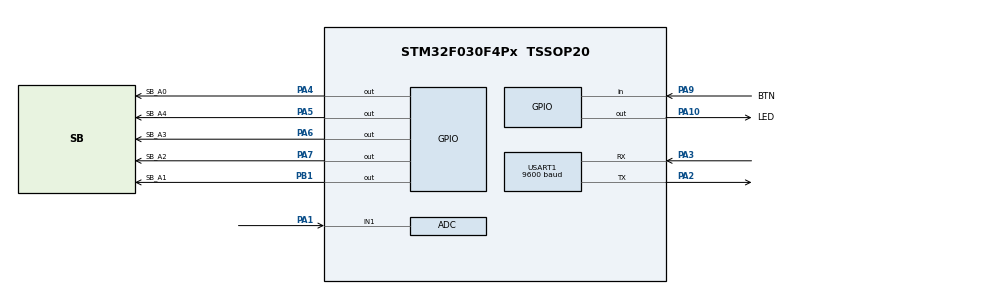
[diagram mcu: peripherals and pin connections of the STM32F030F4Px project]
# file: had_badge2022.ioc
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ADC.ClockPrescaler=ADC_CLOCK_ASYNC_DIV1
ADC.SamplingTime=ADC_SAMPLETIME_55CYCLES_5
Dma.ADC.0.Direction=DMA_PERIPH_TO_MEMORY
Dma.ADC.0.Instance=DMA1_Channel1
Dma.ADC.0.MemDataAlignment=DMA_MDATAALIGN_HALFWORD
Dma.ADC.0.MemInc=DMA_MINC_ENABLE
Dma.ADC.0.Mode=DMA_CIRCULAR
Dma.ADC.0.PeriphDataAlignment=DMA_PDATAALIGN_HALFWORD
Dma.ADC.0.PeriphInc=DMA_PINC_DISABLE
Dma.ADC.0.Priority=DMA_PRIORITY_LOW
Dma.Request0=ADC
Mcu.Family=STM32F0
Mcu.Name=STM32F030F4Px
Mcu.Package=TSSOP20
NVIC.DMA1_Channel1_IRQn=true\:0\:0\:false\:false\:true\:false\:true\:true
NVIC.TIM1_BRK_UP_TRG_COM_IRQn=true\:0\:0\:false\:false\:true\:true\:true\:true
PA0.Signal=ADC_IN0
PA1.Mode=IN1
PA1.Signal=ADC_IN1
PA10.GPIO_Label=LED
PA10.Signal=GPIO_Output
PA13.Mode=Serial_Wire
PA13.Signal=SYS_SWDIO
PA14.Mode=Serial_Wire
PA14.Signal=SYS_SWCLK
PA2.Mode=Asynchronous
PA2.Signal=USART1_TX
PA3.Mode=Asynchronous
PA3.Signal=USART1_RX
PA4.GPIO_Label=SB_A0
PA4.Signal=GPIO_Output
PA5.GPIO_Label=SB_A4
PA5.Signal=GPIO_Output
PA6.GPIO_Label=SB_A3
PA6.Signal=GPIO_Output
PA7.GPIO_Label=SB_A2
PA7.Signal=GPIO_Output
PA9.GPIO_Label=BTN
PA9.GPIO_PuPd=GPIO_PULLUP
PA9.Signal=GPIO_Input
PB1.GPIO_Label=SB_A1
PB1.Signal=GPIO_Output
ProjectManager.HeapSize=0x200
ProjectManager.StackSize=0x400
ProjectManager.TargetToolchain=STM32CubeIDE
RCC.AHBFreq_Value=48000000
RCC.APB1Freq_Value=48000000
RCC.APB1TimFreq_Value=48000000
RCC.HCLKFreq_Value=48000000
RCC.PLLMUL=RCC_PLL_MUL12
RCC.SYSCLKFreq_VALUE=48000000
RCC.SYSCLKSource=RCC_SYSCLKSOURCE_PLLCLK
TIM1.AutoReloadPreload=TIM_AUTORELOAD_PRELOAD_ENABLE
TIM1.Period=4799
TIM1.TIM_MasterOutputTrigger=TIM_TRGO_UPDATE
USART1.BaudRate=9600
USART1.VirtualMode-Asynchronous=VM_ASYNC
VP_TIM1_VS_ClockSourceINT.Mode=Internal
board=custom

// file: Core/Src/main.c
/* USER CODE BEGIN Header */
/**
  ******************************************************************************
  * @file           : main.c
  * @brief          : Main program body
  ******************************************************************************
  * @attention
  *
  * Copyright (c) 2022 STMicroelectronics.
  * All rights reserved.
  *
  * This software is licensed under terms that can be found in the LICENSE file
  * in the root directory of this software component.
  * If no LICENSE file comes with this software, it is provided AS-IS.
  *
  ******************************************************************************
  */
/* USER CODE END Header */
#include "main.h"

void SystemClock_Config(void);
static void MX_GPIO_Init(void);
static void MX_DMA_Init(void);
static void MX_ADC_Init(void);
static void MX_TIM1_Init(void);
static void MX_USART1_UART_Init(void);

int main(void)
{

  /* MCU Configuration--------------------------------------------------------*/

  /* Reset of all peripherals, Initializes the Flash interface and the Systick. */
  LL_APB1_GRP2_EnableClock(LL_APB1_GRP2_PERIPH_SYSCFG);
  LL_APB1_GRP1_EnableClock(LL_APB1_GRP1_PERIPH_PWR);

  /* SysTick_IRQn interrupt configuration */
  NVIC_SetPriority(SysTick_IRQn, 3);

  /* Configure the system clock */
  SystemClock_Config();

  /* Initialize all configured peripherals */
  MX_GPIO_Init();
  MX_DMA_Init();
  MX_ADC_Init();
  MX_TIM1_Init();
  MX_USART1_UART_Init();

  /* Infinite loop */
  /* USER CODE BEGIN WHILE */
  run();
    /* USER CODE END WHILE */

}

void SystemClock_Config(void)
{
  LL_FLASH_SetLatency(LL_FLASH_LATENCY_1);
  while(LL_FLASH_GetLatency() != LL_FLASH_LATENCY_1)
  {
  }
  LL_RCC_HSI_Enable();

   /* Wait till HSI is ready */
  while(LL_RCC_HSI_IsReady() != 1)
  {

  }
  LL_RCC_HSI_SetCalibTrimming(16);
  LL_RCC_HSI14_Enable();

   /* Wait till HSI14 is ready */
  while(LL_RCC_HSI14_IsReady() != 1)
  {

  }
  LL_RCC_HSI14_SetCalibTrimming(16);
  LL_RCC_PLL_ConfigDomain_SYS(LL_RCC_PLLSOURCE_HSI_DIV_2, LL_RCC_PLL_MUL_12);
  LL_RCC_PLL_Enable();

   /* Wait till PLL is ready */
  while(LL_RCC_PLL_IsReady() != 1)
  {

  }
  LL_RCC_SetAHBPrescaler(LL_RCC_SYSCLK_DIV_1);
  LL_RCC_SetAPB1Prescaler(LL_RCC_APB1_DIV_1);
  LL_RCC_SetSysClkSource(LL_RCC_SYS_CLKSOURCE_PLL);

   /* Wait till System clock is ready */
  while(LL_RCC_GetSysClkSource() != LL_RCC_SYS_CLKSOURCE_STATUS_PLL)
  {

  }
  LL_Init1msTick(48000000);
  LL_SetSystemCoreClock(48000000);
  LL_RCC_HSI14_EnableADCControl();
  LL_RCC_SetUSARTClockSource(LL_RCC_USART1_CLKSOURCE_PCLK1);
}

static void MX_ADC_Init(void)
{

  LL_ADC_InitTypeDef ADC_InitStruct = {0};
  LL_ADC_REG_InitTypeDef ADC_REG_InitStruct = {0};

  LL_GPIO_InitTypeDef GPIO_InitStruct = {0};

  /* Peripheral clock enable */
  LL_APB1_GRP2_EnableClock(LL_APB1_GRP2_PERIPH_ADC1);

  LL_AHB1_GRP1_EnableClock(LL_AHB1_GRP1_PERIPH_GPIOA);
  /**ADC GPIO Configuration
  PA0   ------> ADC_IN0
  PA1   ------> ADC_IN1
  */
  GPIO_InitStruct.Pin = LL_GPIO_PIN_0;
  GPIO_InitStruct.Mode = LL_GPIO_MODE_ANALOG;
  GPIO_InitStruct.Pull = LL_GPIO_PULL_NO;
  LL_GPIO_Init(GPIOA, &GPIO_InitStruct);

  GPIO_InitStruct.Pin = LL_GPIO_PIN_1;
  GPIO_InitStruct.Mode = LL_GPIO_MODE_ANALOG;
  GPIO_InitStruct.Pull = LL_GPIO_PULL_NO;
  LL_GPIO_Init(GPIOA, &GPIO_InitStruct);

  /* ADC DMA Init */

  /* ADC Init */
  LL_DMA_SetDataTransferDirection(DMA1, LL_DMA_CHANNEL_1, LL_DMA_DIRECTION_PERIPH_TO_MEMORY);

  LL_DMA_SetChannelPriorityLevel(DMA1, LL_DMA_CHANNEL_1, LL_DMA_PRIORITY_LOW);

  LL_DMA_SetMode(DMA1, LL_DMA_CHANNEL_1, LL_DMA_MODE_CIRCULAR);

  LL_DMA_SetPeriphIncMode(DMA1, LL_DMA_CHANNEL_1, LL_DMA_PERIPH_NOINCREMENT);

  LL_DMA_SetMemoryIncMode(DMA1, LL_DMA_CHANNEL_1, LL_DMA_MEMORY_INCREMENT);

  LL_DMA_SetPeriphSize(DMA1, LL_DMA_CHANNEL_1, LL_DMA_PDATAALIGN_HALFWORD);

  LL_DMA_SetMemorySize(DMA1, LL_DMA_CHANNEL_1, LL_DMA_MDATAALIGN_HALFWORD);

  /** Configure Regular Channel
  */
  LL_ADC_REG_SetSequencerChAdd(ADC1, LL_ADC_CHANNEL_1);

  /** Configure the global features of the ADC (Clock, Resolution, Data Alignment and number of conversion)
  */
  ADC_InitStruct.Clock = LL_ADC_CLOCK_ASYNC;
  ADC_InitStruct.Resolution = LL_ADC_RESOLUTION_12B;
  ADC_InitStruct.DataAlignment = LL_ADC_DATA_ALIGN_RIGHT;
  ADC_InitStruct.LowPowerMode = LL_ADC_LP_MODE_NONE;
  LL_ADC_Init(ADC1, &ADC_InitStruct);
  ADC_REG_InitStruct.TriggerSource = LL_ADC_REG_TRIG_SOFTWARE;
  ADC_REG_InitStruct.SequencerDiscont = LL_ADC_REG_SEQ_DISCONT_DISABLE;
  ADC_REG_InitStruct.ContinuousMode = LL_ADC_REG_CONV_SINGLE;
  ADC_REG_InitStruct.DMATransfer = LL_ADC_REG_DMA_TRANSFER_LIMITED;
  ADC_REG_InitStruct.Overrun = LL_ADC_REG_OVR_DATA_PRESERVED;
  LL_ADC_REG_Init(ADC1, &ADC_REG_InitStruct);
  LL_ADC_REG_SetSequencerScanDirection(ADC1, LL_ADC_REG_SEQ_SCAN_DIR_FORWARD);
  LL_ADC_SetSamplingTimeCommonChannels(ADC1, LL_ADC_SAMPLINGTIME_55CYCLES_5);

}

static void MX_TIM1_Init(void)
{

  LL_TIM_InitTypeDef TIM_InitStruct = {0};

  /* Peripheral clock enable */
  LL_APB1_GRP2_EnableClock(LL_APB1_GRP2_PERIPH_TIM1);

  /* TIM1 interrupt Init */
  NVIC_SetPriority(TIM1_BRK_UP_TRG_COM_IRQn, 0);
  NVIC_EnableIRQ(TIM1_BRK_UP_TRG_COM_IRQn);

  TIM_InitStruct.Prescaler = 0;
  TIM_InitStruct.CounterMode = LL_TIM_COUNTERMODE_UP;
  TIM_InitStruct.Autoreload = 4799;
  TIM_InitStruct.ClockDivision = LL_TIM_CLOCKDIVISION_DIV1;
  TIM_InitStruct.RepetitionCounter = 0;
  LL_TIM_Init(TIM1, &TIM_InitStruct);
  LL_TIM_EnableARRPreload(TIM1);
  LL_TIM_SetClockSource(TIM1, LL_TIM_CLOCKSOURCE_INTERNAL);
  LL_TIM_SetTriggerOutput(TIM1, LL_TIM_TRGO_UPDATE);
  LL_TIM_DisableMasterSlaveMode(TIM1);

}

static void MX_USART1_UART_Init(void)
{

  LL_USART_InitTypeDef USART_InitStruct = {0};

  LL_GPIO_InitTypeDef GPIO_InitStruct = {0};

  /* Peripheral clock enable */
  LL_APB1_GRP2_EnableClock(LL_APB1_GRP2_PERIPH_USART1);

  LL_AHB1_GRP1_EnableClock(LL_AHB1_GRP1_PERIPH_GPIOA);
  /**USART1 GPIO Configuration
  PA2   ------> USART1_TX
  PA3   ------> USART1_RX
  */
  GPIO_InitStruct.Pin = LL_GPIO_PIN_2;
  GPIO_InitStruct.Mode = LL_GPIO_MODE_ALTERNATE;
  GPIO_InitStruct.Speed = LL_GPIO_SPEED_FREQ_HIGH;
  GPIO_InitStruct.OutputType = LL_GPIO_OUTPUT_PUSHPULL;
  GPIO_InitStruct.Pull = LL_GPIO_PULL_NO;
  GPIO_InitStruct.Alternate = LL_GPIO_AF_1;
  LL_GPIO_Init(GPIOA, &GPIO_InitStruct);

  GPIO_InitStruct.Pin = LL_GPIO_PIN_3;
  GPIO_InitStruct.Mode = LL_GPIO_MODE_ALTERNATE;
  GPIO_InitStruct.Speed = LL_GPIO_SPEED_FREQ_HIGH;
  GPIO_InitStruct.OutputType = LL_GPIO_OUTPUT_PUSHPULL;
  GPIO_InitStruct.Pull = LL_GPIO_PULL_NO;
  GPIO_InitStruct.Alternate = LL_GPIO_AF_1;
  LL_GPIO_Init(GPIOA, &GPIO_InitStruct);

  USART_InitStruct.BaudRate = 9600;
  USART_InitStruct.DataWidth = LL_USART_DATAWIDTH_8B;
  USART_InitStruct.StopBits = LL_USART_STOPBITS_1;
  USART_InitStruct.Parity = LL_USART_PARITY_NONE;
  USART_InitStruct.TransferDirection = LL_USART_DIRECTION_TX_RX;
  USART_InitStruct.HardwareFlowControl = LL_USART_HWCONTROL_NONE;
  USART_InitStruct.OverSampling = LL_USART_OVERSAMPLING_16;
  LL_USART_Init(USART1, &USART_InitStruct);
  LL_USART_DisableIT_CTS(USART1);
  LL_USART_ConfigAsyncMode(USART1);
  LL_USART_Enable(USART1);

}

static void MX_DMA_Init(void)
{

  /* Init with LL driver */
  /* DMA controller clock enable */
  LL_AHB1_GRP1_EnableClock(LL_AHB1_GRP1_PERIPH_DMA1);

  /* DMA interrupt init */
  /* DMA1_Channel1_IRQn interrupt configuration */
  NVIC_SetPriority(DMA1_Channel1_IRQn, 0);
  NVIC_EnableIRQ(DMA1_Channel1_IRQn);

}

static void MX_GPIO_Init(void)
{
  LL_GPIO_InitTypeDef GPIO_InitStruct = {0};

  /* GPIO Ports Clock Enable */
  LL_AHB1_GRP1_EnableClock(LL_AHB1_GRP1_PERIPH_GPIOA);
  LL_AHB1_GRP1_EnableClock(LL_AHB1_GRP1_PERIPH_GPIOB);

  /**/
  LL_GPIO_ResetOutputPin(SB_A0_GPIO_Port, SB_A0_Pin);

  /**/
  LL_GPIO_ResetOutputPin(SB_A4_GPIO_Port, SB_A4_Pin);

  /**/
  LL_GPIO_ResetOutputPin(SB_A3_GPIO_Port, SB_A3_Pin);

  /**/
  LL_GPIO_ResetOutputPin(SB_A2_GPIO_Port, SB_A2_Pin);

  /**/
  LL_GPIO_ResetOutputPin(SB_A1_GPIO_Port, SB_A1_Pin);

  /**/
  LL_GPIO_ResetOutputPin(LED_GPIO_Port, LED_Pin);

  /**/
  GPIO_InitStruct.Pin = SB_A0_Pin;
  GPIO_InitStruct.Mode = LL_GPIO_MODE_OUTPUT;
  GPIO_InitStruct.Speed = LL_GPIO_SPEED_FREQ_LOW;
  GPIO_InitStruct.OutputType = LL_GPIO_OUTPUT_PUSHPULL;
  GPIO_InitStruct.Pull = LL_GPIO_PULL_NO;
  LL_GPIO_Init(SB_A0_GPIO_Port, &GPIO_InitStruct);

  /**/
  GPIO_InitStruct.Pin = SB_A4_Pin;
  GPIO_InitStruct.Mode = LL_GPIO_MODE_OUTPUT;
  GPIO_InitStruct.Speed = LL_GPIO_SPEED_FREQ_LOW;
  GPIO_InitStruct.OutputType = LL_GPIO_OUTPUT_PUSHPULL;
  GPIO_InitStruct.Pull = LL_GPIO_PULL_NO;
  LL_GPIO_Init(SB_A4_GPIO_Port, &GPIO_InitStruct);

  /**/
  GPIO_InitStruct.Pin = SB_A3_Pin;
  GPIO_InitStruct.Mode = LL_GPIO_MODE_OUTPUT;
  GPIO_InitStruct.Speed = LL_GPIO_SPEED_FREQ_LOW;
  GPIO_InitStruct.OutputType = LL_GPIO_OUTPUT_PUSHPULL;
  GPIO_InitStruct.Pull = LL_GPIO_PULL_NO;
  LL_GPIO_Init(SB_A3_GPIO_Port, &GPIO_InitStruct);

  /**/
  GPIO_InitStruct.Pin = SB_A2_Pin;
  GPIO_InitStruct.Mode = LL_GPIO_MODE_OUTPUT;
  GPIO_InitStruct.Speed = LL_GPIO_SPEED_FREQ_LOW;
  GPIO_InitStruct.OutputType = LL_GPIO_OUTPUT_PUSHPULL;
  GPIO_InitStruct.Pull = LL_GPIO_PULL_NO;
  LL_GPIO_Init(SB_A2_GPIO_Port, &GPIO_InitStruct);

  /**/
  GPIO_InitStruct.Pin = SB_A1_Pin;
  GPIO_InitStruct.Mode = LL_GPIO_MODE_OUTPUT;
  GPIO_InitStruct.Speed = LL_GPIO_SPEED_FREQ_LOW;
  GPIO_InitStruct.OutputType = LL_GPIO_OUTPUT_PUSHPULL;
  GPIO_InitStruct.Pull = LL_GPIO_PULL_NO;
  LL_GPIO_Init(SB_A1_GPIO_Port, &GPIO_InitStruct);

  /**/
  GPIO_InitStruct.Pin = BTN_Pin;
  GPIO_InitStruct.Mode = LL_GPIO_MODE_INPUT;
  GPIO_InitStruct.Pull = LL_GPIO_PULL_UP;
  LL_GPIO_Init(BTN_GPIO_Port, &GPIO_InitStruct);

  /**/
  GPIO_InitStruct.Pin = LED_Pin;
  GPIO_InitStruct.Mode = LL_GPIO_MODE_OUTPUT;
  GPIO_InitStruct.Speed = LL_GPIO_SPEED_FREQ_LOW;
  GPIO_InitStruct.OutputType = LL_GPIO_OUTPUT_PUSHPULL;
  GPIO_InitStruct.Pull = LL_GPIO_PULL_NO;
  LL_GPIO_Init(LED_GPIO_Port, &GPIO_InitStruct);

}

void Error_Handler(void)
{
  __disable_irq();
  while (1)
  {
  }
}
